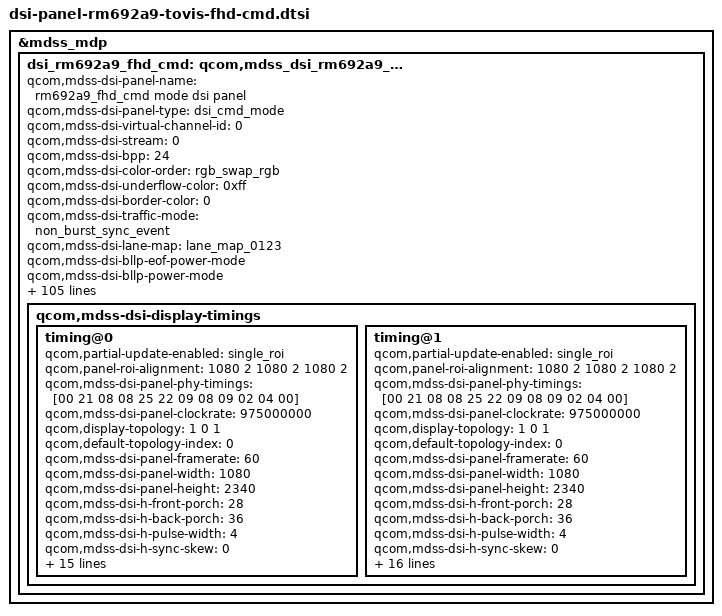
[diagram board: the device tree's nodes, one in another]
/* Copyright (c) 2014, Code Aurora Forum. All rights reserved.
 *
 * This program is free software; you can redistribute it and/or modify
 * it under the terms of the GNU General Public License version 2 and
 * only version 2 as published by the Free Software Foundation.
 *
 * This program is distributed in the hope that it will be useful,
 * but WITHOUT ANY WARRANTY; without even the implied warranty of
 * MERCHANTABILITY or FITNESS FOR A PARTICULAR PURPOSE.  See the
 * GNU General Public License for more details.
 */

&mdss_mdp {
	dsi_rm692a9_fhd_cmd: qcom,mdss_dsi_rm692a9_fhd_cmd {
		qcom,mdss-dsi-panel-name = "rm692a9_fhd_cmd mode dsi panel";
		qcom,mdss-dsi-panel-type = "dsi_cmd_mode";
		qcom,mdss-dsi-virtual-channel-id = <0>;
		qcom,mdss-dsi-stream = <0>;
		qcom,mdss-dsi-bpp = <24>;
		qcom,mdss-dsi-color-order = "rgb_swap_rgb";
		qcom,mdss-dsi-underflow-color = <0xff>;
		qcom,mdss-dsi-border-color = <0>;
		qcom,mdss-dsi-traffic-mode = "non_burst_sync_event";
		qcom,mdss-dsi-lane-map = "lane_map_0123";
		qcom,mdss-dsi-bllp-eof-power-mode;
		qcom,mdss-dsi-bllp-power-mode;
		qcom,mdss-dsi-lane-0-state;
		qcom,mdss-dsi-lane-1-state;
		qcom,mdss-dsi-lane-2-state;
		qcom,mdss-dsi-lane-3-state;
		qcom,mdss-dsi-reset-sequence = <1 10>, <0 2>, <1 10>;
		qcom,mdss-dsi-dma-trigger = "trigger_sw";
		qcom,mdss-dsi-mdp-trigger = "none";
		qcom,mdss-dsi-te-pin-select = <1>;
		qcom,panel-te-source = <1>;
		qcom,mdss-dsi-wr-mem-start = <0x2c>;
		qcom,mdss-dsi-wr-mem-continue = <0x3c>;
		qcom,mdss-dsi-te-dcs-command = <1>;
//		qcom,mdss-dsi-te-check-enable;
//		qcom,mdss-dsi-te-using-te-pin;
		qcom,mdss-dsi-lp11-init;
		qcom,mdss-dsi-tx-eot-append;
		qcom,dsi-ctrl-num = <0>;
		qcom,dsi-phy-num = <0>;
		qcom,dsi-select-clocks = "mux_byte_clk0", "mux_pixel_clk0";
		qcom,ulps-enabled;
		//qcom,null-insertion-enabled;
		qcom,mdss-dsi-t-clk-post = <0x0E>;
		qcom,mdss-dsi-t-clk-pre = <0x36>;

		qcom,mdss-dsi-panel-hdr-enabled;
		qcom,mdss-dsi-panel-hdr-color-primaries = <14880 15935 32435 16555 14945 30910 7790 3415>;
		qcom,mdss-dsi-panel-peak-brightness = <5643000>;
		qcom,mdss-dsi-panel-blackness-level = <6134>;

		qcom,mdss-pan-physical-width-dimension = <68>;
		qcom,mdss-pan-physical-height-dimension = <147>;

		lge,blmap = <
			0
			5 5 5 5 5 5 5 5 5 5 5 6 6 6 7 7 7 7 8 8
			8 9 9 9 10 10 10 11 11 11 11 12 12 12 13 13 14 14 15 16
			16 17 18 18 19 20 20 21 22 23 23 24 25 25 26 27 27 28 29 29
			30 32 34 35 37 39 41 42 44 46 48 49 51 53 55 56 58 60 62 63
			65 68 72 75 72 75 79 82 86 89 92 96 99 103 106 109 113 116 119 123
			126 130 133 136 140 143 147 150 155 160 166 171 176 181 186 192 197 202 207 212
			218 223 228 233 238 243 249 254 259 264 269 275 280 285 293 300 308 315 323 331
			338 343 351 359 366 374 381 389 397 404 412 419 427 435 442 450 457 465 475 486
			497 508 519 530 541 552 563 574 585 596 607 617 628 639 650 661 672 683 694 705
			716 727 738 750 762 774 786 798 810 821 833 845 857 869 881 893 905 917 929 941
			952 964 976 988 1000 1012 1024 1045 1066 1086 1107 1128 1149 1169 1190 1211 1232 1252 1273 1294
			1315 1335 1356 1377 1398 1418 1439 1460 1481 1501 1522 1543 1567 1591 1615 1639 1663 1687 1711 1735
			1759 1783 1807 1832 1856 1880 1904 1928 1952 1976 2000 2024 2048 2072 2096 2099 2103 2106 2109 2113
			2116 2119 2123 2126 2130 2133 2136 2140 2143 2146 2150 2153 2156 2160 2163 2166 2170 2173 2177 2180
			2183 2187 2190 2193 2197 2200 2206 2213 2219 2225 2231 2238 2244 2250 2263 2275 2288 2300 2313 2325
			2338 2350 2367 2383 2400 2417 2433 2450 2467 2483 2500 2517 2533 2550 2567 2583 2600 2617 2633 2650
			2677 2704 2731 2758 2785 2812 2838 2865 2892 2919 2946 2973 3000 3031 3062 3092 3123 3154 3185 3215
			3246 3277 3308 3338 3369 3400 3437 3473 3510 3546 3583 3619 3656 3693 3729 3766 3802 3839 3876 3912
			3949 3985 4022 4058 4095
		>;
		lge,blmap-ex = <
			0
			1 1 1 1 1 1 1 1 1 1 2 2 3 3 4 4 5 5 6 6
			7 7 8 8 9 9 10 10 11 11 12 12 13 13 14 14 15 16 17 18
			19 20 21 22 23 24 25 26 27 28 29 30 31 32 33 33 34 35 36 37
			38 39 40 41 42 43 44 45 46 47 48 49 50 51 52 54 56 58 60 62
			65 67 69 71 73 75 77 79 81 83 85 88 90 92 94 96 98 99 101 102
			104 105 107 108 110 111 112 114 115 117 118 120 121 123 124 125 127 128 129 131
			132 133 135 136 137 138 140 141 142 144 145 146 148 149 149 149 149 149 149 149
			151 153 155 157 159 161 163 165 167 169 171 173 175 177 179 181 183 185 187
		>;
		lge,blmap-ve = <
			0
			5 5 5 5 5 5 5 5 5 5 5 6 6 6 7 7 7 7 8 8
			8 9 9 9 10 10 10 11 11 11 11 12 12 12 13 13 14 15 16 17
			18 19 19 20 21 22 23 24 25 26 27 28 29 30 30 31 32 33 34 35
			36 38 41 43 46 48 51 53 55 58 60 63 65 67 70 72 75 77 80 82
			84 89 94 99 94 99 103 108 113 118 122 127 132 137 141 146 151 156 160 165
			170 175 179 184 189 194 198 203 210 217 224 231 239 246 253 260 267 274 281 288
			296 303 310 317 324 331 338 345 352 360 367 374 381 388 398 409 419 429 440 450
			461 468 478 488 499 509 519 530 540 551 561 571 582 592 602 613 623 633 647 662
			678 693 708 723 739 754 769 785 800 815 831 846 861 876 892 907 922 938 953 968
			983 999 1014 1035 1056 1077 1098 1119 1140 1161 1182 1203 1224 1245 1266 1287 1308 1329 1350 1371
			1392 1413 1434 1455 1476 1497 1518 1544 1571 1597 1624 1650 1677 1703 1730 1756 1783 1809 1836 1862
			1889 1915 1942 1968 1995 2021 2048 2074 2101 2127 2154 2180 2260 2339 2419 2499 2578 2658 2738 2817
			2897 2977 3056 3136 3215 3295 3375 3454 3534 3614 3693 3773 3853 3932 4012 4013 4013 4014 4014 4015
			4015 4016 4017 4017 4018 4018 4019 4020 4020 4021 4021 4022 4022 4023 4024 4024 4025 4025 4026 4027
			4027 4028 4028 4029 4029 4030 4031 4031 4032 4033 4033 4034 4034 4035 4036 4036 4037 4038 4038 4039
			4039 4040 4041 4041 4042 4043 4044 4044 4045 4046 4047 4047 4048 4049 4049 4050 4051 4052 4052 4053
			4054 4055 4056 4056 4057 4058 4059 4060 4061 4061 4062 4063 4064 4065 4066 4067 4068 4069 4070 4070
			4071 4072 4073 4074 4075 4076 4077 4078 4079 4080 4081 4082 4083 4084 4085 4086 4087 4088 4089 4090
			4091 4092 4093 4094 4095
		>;
		lge,blmap-hdr = <
			0
			5 5 5 5 5 5 5 5 5 5 5 6 6 6 7 7 7 7 8 8
			8 9 9 9 10 10 10 11 11 11 11 12 12 12 13 13 14 15 16 17
			18 19 19 20 21 22 23 24 25 26 27 28 29 30 30 31 32 33 34 35
			36 38 41 43 46 48 51 53 55 58 60 63 65 67 70 72 75 77 80 82
			84 89 94 99 94 99 103 108 113 118 122 127 132 137 141 146 151 156 160 165
			170 175 179 184 189 194 198 203 210 217 224 231 239 246 253 260 267 274 281 288
			296 303 310 317 324 331 338 345 352 360 367 374 381 388 398 409 419 429 440 450
			461 468 478 488 499 509 519 530 540 551 561 571 582 592 602 613 623 633 647 662
			678 693 708 723 739 754 769 785 800 815 831 846 861 876 892 907 922 938 953 968
			983 999 1014 1035 1056 1077 1098 1119 1140 1161 1182 1203 1224 1245 1266 1287 1308 1329 1350 1371
			1392 1413 1434 1455 1476 1497 1518 1544 1571 1597 1624 1650 1677 1703 1730 1756 1783 1809 1836 1862
			1889 1915 1942 1968 1995 2021 2048 2074 2101 2127 2154 2180 2260 2339 2419 2499 2578 2658 2738 2817
			2897 2977 3056 3136 3215 3295 3375 3454 3534 3614 3693 3773 3853 3932 4012 4013 4013 4014 4014 4015
			4015 4016 4017 4017 4018 4018 4019 4020 4020 4021 4021 4022 4022 4023 4024 4024 4025 4025 4026 4027
			4027 4028 4028 4029 4029 4030 4031 4031 4032 4033 4033 4034 4034 4035 4036 4036 4037 4038 4038 4039
			4039 4040 4041 4041 4042 4043 4044 4044 4045 4046 4047 4047 4048 4049 4049 4050 4051 4052 4052 4053
			4054 4055 4056 4056 4057 4058 4059 4060 4061 4061 4062 4063 4064 4065 4066 4067 4068 4069 4070 4070
			4071 4072 4073 4074 4075 4076 4077 4078 4079 4080 4081 4082 4083 4084 4085 4086 4087 4088 4089 4090
			4091 4092 4093 4094 4095
		>;


		lge,use-ambient;
		lge,use-post-lp2;
		lge,aod-interface-data = "semi-partial", "semi-partial", "semi-partial";
		lge,mdss-dsi-nolp-command = [
			15 01 00 00 00 00 02 FE 72
			15 01 00 00 00 00 02 69 00
			39 01 00 00 00 00 02 FE 00
			05 01 00 00 50 00 01 38
			39 01 00 00 00 00 02 FE 00
			05 01 00 00 20 00 01 28
			39 01 00 00 00 00 02 FE D0
			39 01 00 00 14 00 02 30 00
			39 01 00 00 00 00 02 FE 20
			39 01 00 00 00 00 02 5F 01
			39 01 00 00 00 00 02 FE 00
			39 01 00 00 00 00 03 51 00 00
			05 01 00 00 20 00 01 29
		];
		lge,mdss-dsi-nolp-command-state = "dsi_lp_mode";

		lge,mdss-dsi-lp2-command = [
			15 01 00 00 00 00 02 FE 72
			15 01 00 00 00 00 02 69 00
			39 01 00 00 00 00 02 FE 00
			05 01 00 00 20 00 01 28
			39 01 00 00 00 00 02 FE D0
			39 01 00 00 14 00 02 30 03
			39 01 00 00 00 00 02 FE 20
			39 01 00 00 00 00 02 5F 07
			39 01 00 00 00 00 02 FE 00
			05 01 00 00 00 00 01 29
			39 01 00 00 00 00 03 51 00 00
		];
		lge,mdss-dsi-lp2-command-state = "dsi_lp_mode";

		lge,mdss-dsi-post-lp2-command = [
			39 01 00 00 64 00 02 FE 00
			05 01 00 00 50 00 01 39
		];
		lge,mdss-dsi-post-lp2-command-state = "dsi_lp_mode";

		lge,use-color-manager;
		lge,color-manager-default-status = <1>;
		lge,mdss-dsi-color-manager-mode-table = <0 1>, <1 1>, <2 1>, <3 1>;
		lge,digital-gamma-absent;

		lge,mdss-dsi-disp-ctrl-command-1 = [
			15 00 00 00 00 00 02 FE 00
			15 00 00 00 00 00 02 5C 00
			15 00 00 00 00 00 02 FE 80
			15 00 00 00 00 00 02 00 4F
			15 00 00 00 00 00 02 05 00
			15 01 00 00 00 00 02 FE 00
		];
		lge,mdss-dsi-disp-ctrl-command-1-state = "dsi_lp_mode";
		lge,mdss-dsi-disp-ctrl-command-2 = [
			15 00 00 00 00 00 02 FE 12
			15 00 00 00 00 00 02 83 10
			15 00 00 00 00 00 02 84 08
			15 01 00 00 00 00 02 FE 00
		];
		lge,mdss-dsi-disp-ctrl-command-2-state = "dsi_lp_mode";

		lge,color-mode-cmds-dummy = [
			/* HUE, SAT enable/disable */
			15 00 00 00 00 00 02 FE 80
			15 00 00 00 00 00 02 00 4F
			/* CE gain */
			15 00 00 00 00 00 02 08 44
			15 00 00 00 00 00 02 09 20
			15 00 00 00 00 00 02 0A EE
			15 00 00 00 00 00 02 0B 02
			15 00 00 00 00 00 02 0C 20
			15 00 00 00 00 00 02 0D F0
			15 00 00 00 00 00 02 0E CF
			15 00 00 00 00 00 02 0F 07
			15 00 00 00 00 00 02 14 CF
			15 00 00 00 00 00 02 15 04
			15 00 00 00 00 00 02 16 F3
			15 00 00 00 00 00 02 17 D7
			15 00 00 00 00 00 02 18 CC
			15 00 00 00 00 00 02 19 7D
			15 00 00 00 00 00 02 1A E3
			15 00 00 00 00 00 02 1B 07
			/* Default CM */
			15 00 00 00 00 00 02 FE 10
			15 00 00 00 00 00 02 00 FF
			15 00 00 00 00 00 02 01 07
			15 00 00 00 00 00 02 02 00
			15 00 00 00 00 00 02 03 00
			15 00 00 00 00 00 02 04 00
			15 00 00 00 00 00 02 05 00
			15 00 00 00 00 00 02 06 FF
			15 00 00 00 00 00 02 07 E7
			15 00 00 00 00 00 02 08 00
			15 00 00 00 00 00 02 09 03
			15 00 00 00 00 00 02 0A 20
			15 00 00 00 00 00 02 0B 00
			15 00 00 00 00 00 02 0C FC
			15 00 00 00 00 00 02 0D 07
			15 01 00 00 00 00 02 FE 00
		];
		lge,color-mode-cmds-dummy-state = "dsi_lp_mode";

		lge,use-color-manager-lut;
		lge,cm-lut-screen-mode-set-name = "def", "cin", "pho", "web", "spo", "gam", "exp";
		lge,cm-lut-screen-mode-set-cnt = <34>;
		lge,cm-lut-screen-mode-set = [
			80 4F 44 20 EE 02 20 F0 CF 07 CF 04 F3 D7 CC 7D E3 07 10 FF 07 00 00 00 00 FF E7 00 03 20 00 FC 07 00
			80 4F 00 FF FF 00 F0 EF C3 01 0F 0F 03 D2 EE 3F 85 07 10 53 07 08 3B 90 00 23 77 02 00 90 00 9F 06 00
			80 4F F0 F0 C0 C0 22 F2 55 07 1F 00 03 43 00 EF 01 0C 10 FF 07 00 35 90 06 BD 46 02 28 80 03 46 06 00
			80 4F F0 FF F0 00 FF FF D1 00 0F 0F 03 02 00 1F 05 04 10 0D 56 1E 36 F0 04 E1 36 02 1D 00 08 07 06 00
			80 4F 46 22 EE 15 21 F0 CF 07 CF 04 F3 C7 CC 7D E3 07 10 2E 07 00 00 00 00 40 E7 00 03 30 00 FB 07 00
			80 4F 46 40 FE 12 21 F0 CF 07 CF 04 F3 C7 CC 7D E3 07 10 7F 07 00 00 00 00 95 D7 00 03 30 00 FA 07 00
			80 4F 44 20 EE 02 20 F0 CF 07 CF 04 F3 D7 CC 7D E3 07 10 FF 07 00 00 00 00 FF E7 00 03 20 00 FC 07 00
		];

		lge,cm-lut-saturation-cnt = <10>;
		lge,cm-lut-saturation = [
			80 4F D9 DD DC DD DD CD 01 00
			80 4F EC EF FE FF FF DF 01 00
			80 4F 44 20 EE 02 20 F0 CF 07
			80 4F FF 44 FF 23 44 B2 CD 0F
			80 4F 1F 56 01 56 56 F3 FF 0F
		];

		lge,cm-lut-sharpness-cnt = <1>;
		lge,cm-lut-sharpness = [08 12 1C 26 30];

		lge,cm-lut-rgb-hue-cnt = <14>;
		lge,cm-lut-rgb-hue = [
			E0 25 01 F5 20 09 72 47 00 01 00 0C 50 06
			80 26 01 F5 20 09 72 A7 00 01 00 0C C0 06
			F0 26 01 F5 20 09 73 07 00 01 00 0C 40 07
			FF 26 01 F5 20 09 11 87 00 01 00 0C 3A 07
			FF 26 01 F5 20 09 7F 86 00 01 00 0C 30 07
			5A 06 01 7E 00 05 B8 47 00 00 F0 05 A4 06
			E8 06 01 7E 00 05 CF A7 00 00 F0 05 17 07
			68 07 01 7E 00 05 B9 07 00 00 F0 05 A3 07
			30 07 01 7E 00 05 00 87 00 00 F0 05 4F 07
			30 07 01 7E 00 05 84 96 00 00 F0 05 3F 07
			EB 06 00 00 00 00 FF 67 00 00 30 00 04 07
			77 07 00 00 00 00 FF 77 00 01 30 00 7C 07
			FF 07 00 00 00 00 FF E7 00 03 20 00 FC 07
			FF 07 00 00 00 00 9B 77 00 01 30 00 F4 07
			FF 07 00 00 00 00 21 87 00 01 30 00 F4 07
			35 06 0A 00 40 01 8F 67 04 43 E0 00 99 06
			C0 06 0A 00 40 01 8F 77 04 43 E0 00 10 07
			60 07 0A 00 40 01 8F E7 04 43 E0 00 B0 07
			60 07 0A 00 40 01 50 77 04 43 E0 00 AF 07
			60 07 0A 00 40 01 DE 76 04 43 E0 00 A7 07
			BA 75 12 00 F0 00 5D 67 08 7F E0 00 69 06
			4A 76 12 00 F0 00 5D 77 08 7F E0 00 DE 06
			EA 76 12 00 F0 00 5D E7 08 7F E0 00 73 07
			EA 76 12 00 F0 00 16 77 08 7F E0 00 70 07
			EA 76 12 00 F0 00 97 76 08 7F E0 00 6A 07
		];

		lge,use-ace-ctrl;
		lge,mdss-dsi-ace-tune-command = [
			15 00 00 00 00 00 02 FE 00
			15 00 00 00 00 00 02 5A 0B
			15 01 00 00 00 00 02 6A 50
		];
		lge,mdss-dsi-ace-command-state = "dsi_lp_mode";
		lge,cm-lut-ace-cnt = <2>;
		lge,cm-lut-ace = [
			0B 50
			0B BF
			00 50
			A8 BF
		];

		lge,disp-br-ctrl-ext-supported;
		lge,ddic-dsi-br-ctrl-ext-command = [
			15 00 00 00 00 00 02 FE 72
			15 00 00 00 00 00 02 69 00
			15 01 00 00 00 00 02 FE 00
		];
		lge,ddic-dsi-br-ctrl-ext-command-state = "dsi_lp_mode";

		lge,use-fp-lhbm;
		lge,fp-hbm-mode-backlight-level = <0x70B>;
		lge,mdss-dsi-fp-lhbm-command = [
			15 00 00 00 00 00 02 FE 00
			15 01 00 00 23 00 02 83 00
		];
		lge,mdss-dsi-fp-lhbm-command-state = "dsi_lp_mode";

		lge,mdss-dsi-fp-lhbm-ready-command = [
			15 00 00 00 00 00 02 FE 74
			15 00 00 00 00 00 02 3D FF
			15 00 00 00 00 00 02 3A FF
			15 00 00 00 00 00 02 FE D0
			15 00 00 00 00 00 02 99 03
			15 01 00 00 23 00 02 FE 00
		];
		lge,mdss-dsi-fp-lhbm-ready-command-state = "dsi_lp_mode";

		lge,mdss-dsi-fp-lhbm-exit-command = [
			15 00 00 00 00 00 02 FE 74
			15 00 00 00 00 00 02 3D 3F
			15 00 00 00 00 00 02 3A F3
			15 00 00 00 00 00 02 FE D0
			15 00 00 00 00 00 02 99 01
			15 01 00 00 23 00 02 FE 00
		];
		lge,mdss-dsi-fp-lhbm-exit-command-state = "dsi_lp_mode";
		qcom,mdss-dsi-display-timings {
			timing@0{
				qcom,partial-update-enabled = "single_roi";
				qcom,panel-roi-alignment = <1080 2 1080 2 1080 2>;
				qcom,mdss-dsi-panel-phy-timings = [00 21 08 08 25 22 09 08 09 02 04 00];
				qcom,mdss-dsi-panel-clockrate = <975000000>;
				qcom,display-topology = <1 0 1>;
				qcom,default-topology-index = <0>;
				qcom,mdss-dsi-panel-framerate = <60>;
				qcom,mdss-dsi-panel-width = <1080>;
				qcom,mdss-dsi-panel-height = <2340>;
				qcom,mdss-dsi-h-front-porch = <28>;
				qcom,mdss-dsi-h-back-porch = <36>;
				qcom,mdss-dsi-h-pulse-width = <4>;
				qcom,mdss-dsi-h-sync-skew = <0>;
				qcom,mdss-dsi-v-back-porch = <4>;
				qcom,mdss-dsi-v-front-porch = <12>;
				qcom,mdss-dsi-v-pulse-width = <4>;
				qcom,mdss-dsi-h-left-border = <0>;
				qcom,mdss-dsi-h-right-border = <0>;
				qcom,mdss-dsi-v-top-border = <0>;
				qcom,mdss-dsi-v-bottom-border = <0>;
				qcom,mdss-dsi-h-sync-pulse = <0>;
				qcom,mdss-mdp-transfer-time-us = <15200>;

				qcom,mdss-dsi-on-command = [
					39 01 00 00 00 00 02 FE D0
					39 01 00 00 00 00 02 99 01
					39 01 00 00 00 00 02 FE 40
					39 01 00 00 00 00 02 6F 00
					39 01 00 00 00 00 02 9A 01
					39 01 00 00 00 00 02 FE 00
					39 01 00 00 00 00 02 5A 0B
					39 01 00 00 00 00 02 5C 00
					39 01 00 00 00 00 02 C2 08
					39 01 00 00 00 00 02 35 00
					39 01 00 00 00 00 03 51 00 00
					05 01 00 00 78 00 01 11
					05 01 00 00 3C 00 01 29
				];
				qcom,mdss-dsi-on-command-state = "dsi_lp_mode";

				qcom,mdss-dsi-off-command = [
					39 01 00 00 00 00 02 FE 00
					05 01 00 00 50 00 01 38
					39 01 00 00 00 00 02 FE 00
					05 01 00 00 78 00 01 28
					39 01 00 00 00 00 02 FE 00
					05 01 00 00 0A 00 01 10
				];
				qcom,mdss-dsi-off-command-state = "dsi_lp_mode";
			};
			timing@1{
				qcom,partial-update-enabled = "single_roi";
				qcom,panel-roi-alignment = <1080 2 1080 2 1080 2>;
				qcom,mdss-dsi-panel-phy-timings = [00 21 08 08 25 22 09 08 09 02 04 00];
				qcom,mdss-dsi-panel-clockrate = <975000000>;
				qcom,display-topology = <1 0 1>;
				qcom,default-topology-index = <0>;
				qcom,mdss-dsi-panel-framerate = <60>;
				qcom,mdss-dsi-panel-width = <1080>;
				qcom,mdss-dsi-panel-height = <2340>;
				qcom,mdss-dsi-h-front-porch = <28>;
				qcom,mdss-dsi-h-back-porch = <36>;
				qcom,mdss-dsi-h-pulse-width = <4>;
				qcom,mdss-dsi-h-sync-skew = <0>;
				qcom,mdss-dsi-v-back-porch = <4>;
				qcom,mdss-dsi-v-front-porch = <12>;
				qcom,mdss-dsi-v-pulse-width = <4>;
				qcom,mdss-dsi-h-left-border = <0>;
				qcom,mdss-dsi-h-right-border = <0>;
				qcom,mdss-dsi-v-top-border = <0>;
				qcom,mdss-dsi-v-bottom-border = <0>;
				qcom,mdss-dsi-h-sync-pulse = <0>;
				qcom,mdss-mdp-transfer-time-us = <15200>;
				lge,mdss-dsi-panel-framerate-div = <2>;

				qcom,mdss-dsi-on-command = [
					39 01 00 00 00 00 02 FE D0
					39 01 00 00 00 00 02 99 01
					39 01 00 00 00 00 02 FE 40
					39 01 00 00 00 00 02 6F 00
					39 01 00 00 00 00 02 9A 01
					39 01 00 00 00 00 02 FE 00
					39 01 00 00 00 00 02 5A 0B
					39 01 00 00 00 00 02 5C 00
					39 01 00 00 00 00 02 C2 08
					39 01 00 00 00 00 02 35 00
					39 01 00 00 00 00 03 51 00 00
					05 01 00 00 78 00 01 11
					05 01 00 00 3C 00 01 29
				];
				qcom,mdss-dsi-on-command-state = "dsi_lp_mode";

				qcom,mdss-dsi-off-command = [
					39 01 00 00 00 00 02 FE 00
					05 01 00 00 50 00 01 38
					39 01 00 00 00 00 02 FE 00
					05 01 00 00 78 00 01 28
					39 01 00 00 00 00 02 FE 00
					05 01 00 00 0A 00 01 10
				];
				qcom,mdss-dsi-off-command-state = "dsi_lp_mode";
			};
		};
	};
};

